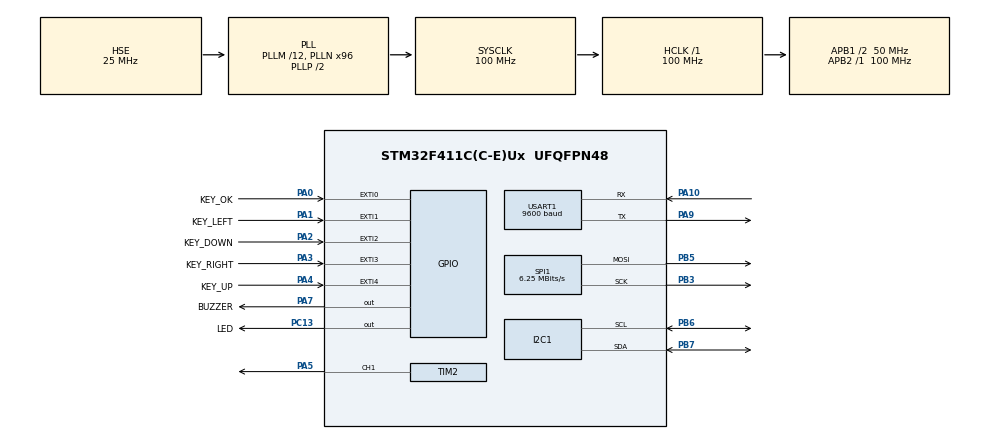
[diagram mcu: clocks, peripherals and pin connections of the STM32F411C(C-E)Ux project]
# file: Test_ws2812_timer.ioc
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Dma.I2C1_TX.0.Direction=DMA_MEMORY_TO_PERIPH
Dma.I2C1_TX.0.FIFOMode=DMA_FIFOMODE_DISABLE
Dma.I2C1_TX.0.Instance=DMA1_Stream1
Dma.I2C1_TX.0.MemDataAlignment=DMA_MDATAALIGN_BYTE
Dma.I2C1_TX.0.MemInc=DMA_MINC_ENABLE
Dma.I2C1_TX.0.Mode=DMA_NORMAL
Dma.I2C1_TX.0.PeriphDataAlignment=DMA_PDATAALIGN_BYTE
Dma.I2C1_TX.0.PeriphInc=DMA_PINC_DISABLE
Dma.I2C1_TX.0.Priority=DMA_PRIORITY_HIGH
Dma.Request0=I2C1_TX
Dma.Request1=TIM2_CH1
Dma.TIM2_CH1.1.Direction=DMA_MEMORY_TO_PERIPH
Dma.TIM2_CH1.1.FIFOMode=DMA_FIFOMODE_DISABLE
Dma.TIM2_CH1.1.Instance=DMA1_Stream5
Dma.TIM2_CH1.1.MemDataAlignment=DMA_MDATAALIGN_WORD
Dma.TIM2_CH1.1.MemInc=DMA_MINC_ENABLE
Dma.TIM2_CH1.1.Mode=DMA_CIRCULAR
Dma.TIM2_CH1.1.PeriphDataAlignment=DMA_PDATAALIGN_WORD
Dma.TIM2_CH1.1.PeriphInc=DMA_PINC_DISABLE
Dma.TIM2_CH1.1.Priority=DMA_PRIORITY_VERY_HIGH
I2C1.I2C_Mode=I2C_Fast
Mcu.Family=STM32F4
Mcu.Name=STM32F411C(C-E)Ux
Mcu.Package=UFQFPN48
NVIC.DMA1_Stream1_IRQn=true\:0\:0\:false\:false\:true\:false\:true
NVIC.DMA1_Stream5_IRQn=true\:0\:0\:false\:false\:true\:false\:true
NVIC.EXTI0_IRQn=true\:0\:0\:false\:false\:true\:true\:true
NVIC.EXTI1_IRQn=true\:0\:0\:false\:false\:true\:true\:true
NVIC.EXTI2_IRQn=true\:0\:0\:false\:false\:true\:true\:true
NVIC.EXTI3_IRQn=true\:0\:0\:false\:false\:true\:true\:true
NVIC.EXTI4_IRQn=true\:0\:0\:false\:false\:true\:true\:true
NVIC.I2C1_EV_IRQn=true\:0\:0\:false\:false\:true\:true\:true
NVIC.PriorityGroup=NVIC_PRIORITYGROUP_4
NVIC.SPI1_IRQn=true\:0\:0\:false\:false\:true\:true\:true
NVIC.TIM2_IRQn=true\:0\:0\:false\:false\:true\:true\:true
NVIC.USART1_IRQn=true\:0\:0\:false\:false\:true\:true\:true
PA0-WKUP.GPIO_Label=KEY_OK
PA0-WKUP.GPIO_ModeDefaultEXTI=GPIO_MODE_IT_RISING_FALLING
PA0-WKUP.Signal=GPXTI0
PA1.GPIO_Label=KEY_LEFT
PA1.GPIO_ModeDefaultEXTI=GPIO_MODE_IT_RISING_FALLING
PA1.Signal=GPXTI1
PA10.Mode=Asynchronous
PA10.Signal=USART1_RX
PA13.Mode=Serial_Wire
PA13.Signal=SYS_JTMS-SWDIO
PA14.Mode=Serial_Wire
PA14.Signal=SYS_JTCK-SWCLK
PA2.GPIO_Label=KEY_DOWN
PA2.GPIO_ModeDefaultEXTI=GPIO_MODE_IT_RISING_FALLING
PA2.Signal=GPXTI2
PA3.GPIO_Label=KEY_RIGHT
PA3.GPIO_ModeDefaultEXTI=GPIO_MODE_IT_RISING_FALLING
PA3.Signal=GPXTI3
PA4.GPIO_Label=KEY_UP
PA4.GPIO_ModeDefaultEXTI=GPIO_MODE_IT_RISING_FALLING
PA4.Signal=GPXTI4
PA5.Signal=S_TIM2_CH1_ETR
PA7.GPIO_Label=BUZZER
PA7.Signal=GPIO_Output
PA9.Mode=Asynchronous
PA9.Signal=USART1_TX
PB3.Mode=TX_Only_Simplex_Unidirect_Master
PB3.Signal=SPI1_SCK
PB5.Mode=TX_Only_Simplex_Unidirect_Master
PB5.Signal=SPI1_MOSI
PB6.GPIO_Pu=GPIO_PULLUP
PB6.Mode=I2C
PB6.Signal=I2C1_SCL
PB7.GPIO_Pu=GPIO_PULLUP
PB7.Mode=I2C
PB7.Signal=I2C1_SDA
PC13-ANTI_TAMP.GPIO_Label=LED
PC13-ANTI_TAMP.PinState=GPIO_PIN_SET
PC13-ANTI_TAMP.Signal=GPIO_Output
PC14-OSC32_IN.Mode=LSE-External-Oscillator
PC14-OSC32_IN.Signal=RCC_OSC32_IN
PC15-OSC32_OUT.Mode=LSE-External-Oscillator
PC15-OSC32_OUT.Signal=RCC_OSC32_OUT
PH0\ -\ OSC_IN.Mode=HSE-External-Oscillator
PH0\ -\ OSC_IN.Signal=RCC_OSC_IN
PH1\ -\ OSC_OUT.Mode=HSE-External-Oscillator
PH1\ -\ OSC_OUT.Signal=RCC_OSC_OUT
ProjectManager.HeapSize=0x200
ProjectManager.StackSize=0x400
ProjectManager.TargetToolchain=STM32CubeIDE
RCC.48MHZClocksFreq_Value=50000000
RCC.AHBFreq_Value=100000000
RCC.APB1CLKDivider=RCC_HCLK_DIV2
RCC.APB1Freq_Value=50000000
RCC.APB1TimFreq_Value=100000000
RCC.APB2Freq_Value=100000000
RCC.APB2TimFreq_Value=100000000
RCC.CortexFreq_Value=100000000
RCC.HCLKFreq_Value=100000000
RCC.HSE_VALUE=25000000
RCC.HSI_VALUE=16000000
RCC.PLLM=12
RCC.PLLN=96
RCC.PLLSourceVirtual=RCC_PLLSOURCE_HSE
RCC.RCC_RTC_Clock_Source=RCC_RTCCLKSOURCE_LSE
RCC.RCC_RTC_Clock_SourceVirtual=RCC_RTCCLKSOURCE_LSE
RCC.SYSCLKFreq_VALUE=100000000
RCC.SYSCLKSource=RCC_SYSCLKSOURCE_PLLCLK
RCC.VCOOutputFreq_Value=200000000
RTC.Date=28
RTC.Hours=12
RTC.Month=RTC_MONTH_MARCH
RTC.WeekDay=RTC_WEEKDAY_SATURDAY
RTC.Year=20
SH.S_TIM2_CH1_ETR.0=TIM2_CH1,PWM Generation1 CH1
SPI1.BaudRatePrescaler=SPI_BAUDRATEPRESCALER_16
SPI1.CalculateBaudRate=6.25 MBits/s
SPI1.Direction=SPI_DIRECTION_2LINES
SPI1.Mode=SPI_MODE_MASTER
SPI1.VirtualType=VM_MASTER
TIM2.Channel-PWM\ Generation1\ CH1=TIM_CHANNEL_1
TIM2.Period=125
TIM2.Prescaler=0
TIM2.TIM_MasterOutputTrigger=TIM_TRGO_UPDATE
USART1.BaudRate=9600
USART1.VirtualMode=VM_ASYNC
VP_RTC_VS_RTC_Activate.Mode=RTC_Enabled
VP_RTC_VS_RTC_Calendar.Mode=RTC_Calendar
VP_TIM2_VS_ClockSourceINT.Mode=Internal
board=custom

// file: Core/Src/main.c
/* USER CODE BEGIN Header */
/**
  ******************************************************************************
  * @file           : main.c
  * @brief          : Main program body
  ******************************************************************************
  * @attention
  *
  * <h2><center>&copy; Copyright (c) 2021 STMicroelectronics.
  * All rights reserved.</center></h2>
  *
  * This software component is licensed by ST under BSD 3-Clause license,
  * the "License"; You may not use this file except in compliance with the
  * License. You may obtain a copy of the License at:
  *                        opensource.org/licenses/BSD-3-Clause
  *
  ******************************************************************************
  */
/* USER CODE END Header */
#include "main.h"
#include "dma.h"
#include "i2c.h"
#include "rtc.h"
#include "spi.h"
#include "tim.h"
#include "usart.h"
#include "gpio.h"

/* USER CODE BEGIN Includes */
#include "ws2812b.h"
/* USER CODE END Includes */

/* USER CODE BEGIN PV */
int kelvin=1000;
/* USER CODE END PV */

void SystemClock_Config(void);

int main(void)
{

  /* MCU Configuration--------------------------------------------------------*/

  /* Reset of all peripherals, Initializes the Flash interface and the Systick. */
  HAL_Init();

  /* Configure the system clock */
  SystemClock_Config();

  /* Initialize all configured peripherals */
  MX_GPIO_Init();
  MX_DMA_Init();
  MX_I2C1_Init();
  MX_RTC_Init();
  MX_USART1_UART_Init();
  MX_TIM2_Init();
  MX_SPI1_Init();
  /* USER CODE BEGIN 2 */
  ws2812b_init(&htim2, TIM_CHANNEL_1);

  /* USER CODE END 2 */

  /* Infinite loop */
  /* USER CODE BEGIN WHILE */
  while (1)
  {
	for (int i = 0; i < 8; ++i)	ws2812b_setKelvin(i, kelvin,1);

	ws2812b_refresh();
    /* USER CODE END WHILE */

  }
}

void SystemClock_Config(void)
{
  RCC_OscInitTypeDef RCC_OscInitStruct = {0};
  RCC_ClkInitTypeDef RCC_ClkInitStruct = {0};

  /** Configure the main internal regulator output voltage
  */
  __HAL_RCC_PWR_CLK_ENABLE();
  __HAL_PWR_VOLTAGESCALING_CONFIG(PWR_REGULATOR_VOLTAGE_SCALE1);
  /** Initializes the RCC Oscillators according to the specified parameters
  * in the RCC_OscInitTypeDef structure.
  */
  RCC_OscInitStruct.OscillatorType = RCC_OSCILLATORTYPE_HSE|RCC_OSCILLATORTYPE_LSE;
  RCC_OscInitStruct.HSEState = RCC_HSE_ON;
  RCC_OscInitStruct.LSEState = RCC_LSE_ON;
  RCC_OscInitStruct.PLL.PLLState = RCC_PLL_ON;
  RCC_OscInitStruct.PLL.PLLSource = RCC_PLLSOURCE_HSE;
  RCC_OscInitStruct.PLL.PLLM = 12;
  RCC_OscInitStruct.PLL.PLLN = 96;
  RCC_OscInitStruct.PLL.PLLP = RCC_PLLP_DIV2;
  RCC_OscInitStruct.PLL.PLLQ = 4;
  if (HAL_RCC_OscConfig(&RCC_OscInitStruct) != HAL_OK)
  {
    Error_Handler();
  }
  /** Initializes the CPU, AHB and APB buses clocks
  */
  RCC_ClkInitStruct.ClockType = RCC_CLOCKTYPE_HCLK|RCC_CLOCKTYPE_SYSCLK
                              |RCC_CLOCKTYPE_PCLK1|RCC_CLOCKTYPE_PCLK2;
  RCC_ClkInitStruct.SYSCLKSource = RCC_SYSCLKSOURCE_PLLCLK;
  RCC_ClkInitStruct.AHBCLKDivider = RCC_SYSCLK_DIV1;
  RCC_ClkInitStruct.APB1CLKDivider = RCC_HCLK_DIV2;
  RCC_ClkInitStruct.APB2CLKDivider = RCC_HCLK_DIV1;

  if (HAL_RCC_ClockConfig(&RCC_ClkInitStruct, FLASH_LATENCY_3) != HAL_OK)
  {
    Error_Handler();
  }
}

void Error_Handler(void)
{
  __disable_irq();
  while (1)
  {
  }
}

/************************ (C) COPYRIGHT STMicroelectronics *****END OF FILE****/
